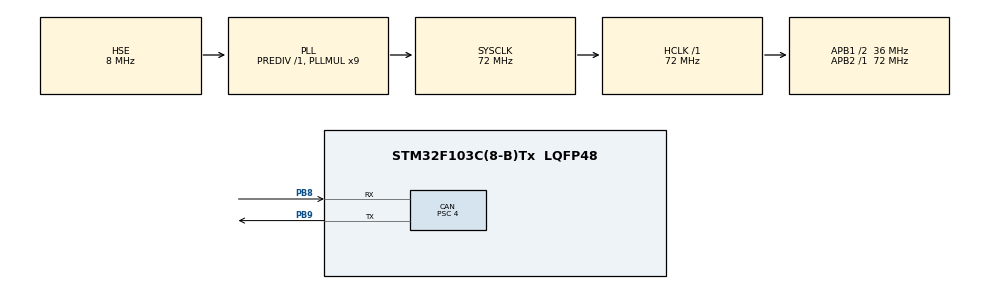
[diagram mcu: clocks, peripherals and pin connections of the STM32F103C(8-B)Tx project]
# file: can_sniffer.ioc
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CAN.BS1=CAN_BS1_15TQ
CAN.BS2=CAN_BS2_2TQ
CAN.CalculateTimeBit=2000
CAN.CalculateTimeQuantum=111.11111111111111
CAN.Mode=CAN_MODE_NORMAL
CAN.Prescaler=4
Mcu.Family=STM32F1
Mcu.Name=STM32F103C(8-B)Tx
Mcu.Package=LQFP48
NVIC.PriorityGroup=NVIC_PRIORITYGROUP_4
NVIC.USB_LP_CAN1_RX0_IRQn=true\:0\:0\:false\:false\:true\:true\:true
PB8.Mode=Master
PB8.Signal=CAN_RX
PB9.Mode=Master
PB9.Signal=CAN_TX
PD0-OSC_IN.Mode=HSE-External-Oscillator
PD0-OSC_IN.Signal=RCC_OSC_IN
PD1-OSC_OUT.Mode=HSE-External-Oscillator
PD1-OSC_OUT.Signal=RCC_OSC_OUT
ProjectManager.HeapSize=0x200
ProjectManager.StackSize=0x400
ProjectManager.TargetToolchain=STM32CubeIDE
RCC.AHBFreq_Value=72000000
RCC.APB1CLKDivider=RCC_HCLK_DIV2
RCC.APB1Freq_Value=36000000
RCC.APB1TimFreq_Value=72000000
RCC.APB2Freq_Value=72000000
RCC.APB2TimFreq_Value=72000000
RCC.HCLKFreq_Value=72000000
RCC.PLLMUL=RCC_PLL_MUL9
RCC.PLLSourceVirtual=RCC_PLLSOURCE_HSE
RCC.SYSCLKFreq_VALUE=72000000
RCC.SYSCLKSource=RCC_SYSCLKSOURCE_PLLCLK
RCC.USBFreq_Value=72000000
VP_SYS_VS_ND.Mode=No_Debug
board=custom

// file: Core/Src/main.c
/* USER CODE BEGIN Header */
/**
  ******************************************************************************
  * @file           : main.c
  * @brief          : Main program body
  ******************************************************************************
  * @attention
  *
  * <h2><center>&copy; Copyright (c) 2020 STMicroelectronics.
  * All rights reserved.</center></h2>
  *
  * This software component is licensed by ST under BSD 3-Clause license,
  * the "License"; You may not use this file except in compliance with the
  * License. You may obtain a copy of the License at:
  *                        opensource.org/licenses/BSD-3-Clause
  *
  ******************************************************************************
  */
/* USER CODE END Header */

#include "main.h"

CAN_HandleTypeDef hcan;

void SystemClock_Config(void);
static void MX_GPIO_Init(void);
static void MX_CAN_Init(void);

int main(void)
{

  /* MCU Configuration--------------------------------------------------------*/

  /* Reset of all peripherals, Initializes the Flash interface and the Systick. */
  HAL_Init();

  /* Configure the system clock */
  SystemClock_Config();

  /* Initialize all configured peripherals */
  MX_GPIO_Init();
  MX_CAN_Init();
  /* USER CODE BEGIN 2 */

#define RCC_APB2Periph_GPIOC             ((uint32_t)0x00000010)

  /* USER CODE END 2 */

  /* Infinite loop */
  /* USER CODE BEGIN WHILE */
  RCC->APB2ENR |= RCC_APB2Periph_GPIOC; // РІРєР»СЋС‡Р°РµРј С‚Р°РєС‚РёСЂРѕРІР°РЅРёРµ РїРѕСЂС‚Р°
  GPIOC->CRH |= (0x3 << 20); // СЃС‚Р°РІРёРј С‡Р°СЃС‚РѕС‚Сѓ 50 РњР“С†
  volatile long i = 0;
  while (1)
  {
	  GPIOC->BSRR = GPIO_BSRR_BR13;
	  for(i = 0; i < 1000*1000; i++){;};
	  GPIOC->BSRR = GPIO_BSRR_BS13;
	  for(i = 0; i < 1000*1000; i++){;};
    /* USER CODE END WHILE */

  }
}

void SystemClock_Config(void)
{
  RCC_OscInitTypeDef RCC_OscInitStruct = {0};
  RCC_ClkInitTypeDef RCC_ClkInitStruct = {0};

  /** Initializes the CPU, AHB and APB busses clocks
  */
  RCC_OscInitStruct.OscillatorType = RCC_OSCILLATORTYPE_HSE;
  RCC_OscInitStruct.HSEState = RCC_HSE_ON;
  RCC_OscInitStruct.HSEPredivValue = RCC_HSE_PREDIV_DIV1;
  RCC_OscInitStruct.HSIState = RCC_HSI_ON;
  RCC_OscInitStruct.PLL.PLLState = RCC_PLL_ON;
  RCC_OscInitStruct.PLL.PLLSource = RCC_PLLSOURCE_HSE;
  RCC_OscInitStruct.PLL.PLLMUL = RCC_PLL_MUL9;
  if (HAL_RCC_OscConfig(&RCC_OscInitStruct) != HAL_OK)
  {
    Error_Handler();
  }
  /** Initializes the CPU, AHB and APB busses clocks
  */
  RCC_ClkInitStruct.ClockType = RCC_CLOCKTYPE_HCLK|RCC_CLOCKTYPE_SYSCLK
                              |RCC_CLOCKTYPE_PCLK1|RCC_CLOCKTYPE_PCLK2;
  RCC_ClkInitStruct.SYSCLKSource = RCC_SYSCLKSOURCE_PLLCLK;
  RCC_ClkInitStruct.AHBCLKDivider = RCC_SYSCLK_DIV1;
  RCC_ClkInitStruct.APB1CLKDivider = RCC_HCLK_DIV2;
  RCC_ClkInitStruct.APB2CLKDivider = RCC_HCLK_DIV1;

  if (HAL_RCC_ClockConfig(&RCC_ClkInitStruct, FLASH_LATENCY_2) != HAL_OK)
  {
    Error_Handler();
  }
}

static void MX_CAN_Init(void)
{

  hcan.Instance = CAN1;
  hcan.Init.Prescaler = 4;
  hcan.Init.Mode = CAN_MODE_NORMAL;
  hcan.Init.SyncJumpWidth = CAN_SJW_1TQ;
  hcan.Init.TimeSeg1 = CAN_BS1_15TQ;
  hcan.Init.TimeSeg2 = CAN_BS2_2TQ;
  hcan.Init.TimeTriggeredMode = DISABLE;
  hcan.Init.AutoBusOff = DISABLE;
  hcan.Init.AutoWakeUp = DISABLE;
  hcan.Init.AutoRetransmission = DISABLE;
  hcan.Init.ReceiveFifoLocked = DISABLE;
  hcan.Init.TransmitFifoPriority = DISABLE;
  if (HAL_CAN_Init(&hcan) != HAL_OK)
  {
    Error_Handler();
  }

}

static void MX_GPIO_Init(void)
{

  /* GPIO Ports Clock Enable */
  __HAL_RCC_GPIOD_CLK_ENABLE();
  __HAL_RCC_GPIOB_CLK_ENABLE();

}

void Error_Handler(void)
{
}

/************************ (C) COPYRIGHT STMicroelectronics *****END OF FILE****/
